AUTOSAR XML (schema 4-3-0)
package /MICROSAR/BswM_swc
  data type mapping set BswMMappingSet  # Contains Mapping for ModeDeclarations Groups which are provided by BswM.
    mode-request-type-maps:
      implementation-data-type=uint8, mode-group=ErrorMemoryLockSignalReceptionMode
      implementation-data-type=uint8, mode-group=StdDiag_SessionModeGroup
      implementation-data-type=NormalCommunicationModeType, mode-group=StdDiag_NormalCommunicationModeGroup
      implementation-data-type=uint8, mode-group=Vin_VinComMode
      implementation-data-type=uint8, mode-group=DarhReportErrorMode
      implementation-data-type=Coding_ConditionModeType, mode-group=Coding_ConditionMode
      implementation-data-type=uint8, mode-group=Coding_BusComMode
      implementation-data-type=Dlog_LifeCycleRequestType, mode-group=Dlog_LifeCycle
      implementation-data-type=StdDiag_LifeCycleRequestType, mode-group=StdDiag_LifeCycle
      implementation-data-type=SysTime_LifeCycleRequestType, mode-group=SysTime_LifeCycle
      implementation-data-type=Omc_LifeCycleRequestType, mode-group=Omc_LifeCycle
      implementation-data-type=Dcm_DiagnosticSessionControlType, mode-group=DcmDiagnosticSessionControl
      implementation-data-type=Darh_LifeCycleRequestType, mode-group=Darh_LifeCycle
      implementation-data-type=Vin_LifeCycleRequestType, mode-group=Vin_LifeCycle
      implementation-data-type=Dcm_EcuResetType, mode-group=DcmEcuReset
      implementation-data-type=Dcm_CommunicationModeType, mode-group=DcmCommunicationControl
      implementation-data-type=Coding_LifeCycleRequestType, mode-group=Coding_LifeCycle
      implementation-data-type=Stm_CentralErrorLockType, mode-group=Stm_CentralErrorLockMode
package /MICROSAR/BswM_swc/ComponentTypes
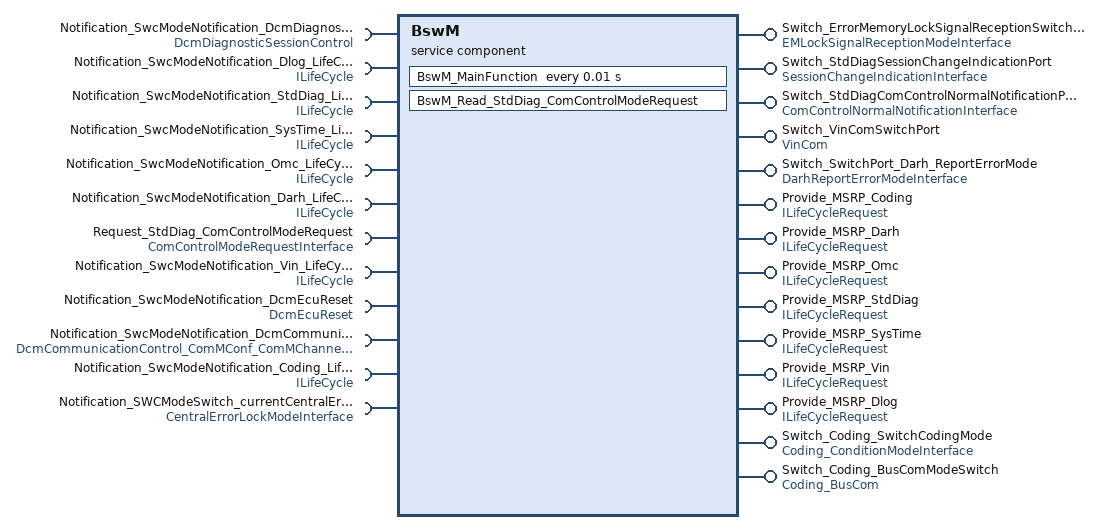
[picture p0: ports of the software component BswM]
  service sw component type BswM: category=SERVICE_COMPONENT
    require port Notification_SwcModeNotification_DcmDiagnosticSessionControl: required-interface=DcmDiagnosticSessionControl
    provide port Switch_ErrorMemoryLockSignalReceptionSwitchPort: provided-interface=EMLockSignalReceptionModeInterface
    provide port Switch_StdDiagSessionChangeIndicationPort: provided-interface=SessionChangeIndicationInterface
    provide port Switch_StdDiagComControlNormalNotificationPort: provided-interface=ComControlNormalNotificationInterface
    6 x require port:
      Notification_SwcModeNotification_Dlog_LifeCycle: required-interface=ILifeCycle
      Notification_SwcModeNotification_StdDiag_LifeCycle: required-interface=ILifeCycle
      Notification_SwcModeNotification_SysTime_LifeCycle: required-interface=ILifeCycle
      Notification_SwcModeNotification_Omc_LifeCycle: required-interface=ILifeCycle
      Notification_SwcModeNotification_Darh_LifeCycle: required-interface=ILifeCycle
      Request_StdDiag_ComControlModeRequest: nonqueued-receiver-com-spec{data-element=requestedMode, handle-out-of-range-status=SILENT, init-value=DISABLE_RX_AND_TX_NORMAL}, required-interface=ComControlModeRequestInterface
    provide port Switch_VinComSwitchPort: provided-interface=VinCom
    4 x require port:
      Notification_SwcModeNotification_Vin_LifeCycle: required-interface=ILifeCycle
      Notification_SwcModeNotification_DcmEcuReset: required-interface=DcmEcuReset
      Notification_SwcModeNotification_DcmCommunicationControl_ComMConf_ComMChannel_A_FlexRay_372befd6: required-interface=DcmCommunicationControl_ComMConf_ComMChannel_A_FlexRay_372befd6
      Notification_SwcModeNotification_Coding_LifeCycle: required-interface=ILifeCycle
    provide port Switch_SwitchPort_Darh_ReportErrorMode: provided-interface=DarhReportErrorModeInterface
    require port Notification_SWCModeSwitch_currentCentralErrorLockMode: required-interface=CentralErrorLockModeInterface
    9 x provide port:
      Provide_MSRP_Coding: nonqueued-sender-com-spec=requestMode, provided-interface=ILifeCycleRequest
      Provide_MSRP_Darh: nonqueued-sender-com-spec=requestMode, provided-interface=ILifeCycleRequest
      Provide_MSRP_Omc: nonqueued-sender-com-spec=requestMode, provided-interface=ILifeCycleRequest
      Provide_MSRP_StdDiag: nonqueued-sender-com-spec{data-element=requestMode, init-value=STDDIAG_STOPPED}, provided-interface=ILifeCycleRequest
      Provide_MSRP_SysTime: nonqueued-sender-com-spec=requestMode, provided-interface=ILifeCycleRequest
      Provide_MSRP_Vin: nonqueued-sender-com-spec{data-element=requestMode, init-value=VIN_STOPPED}, provided-interface=ILifeCycleRequest
      Provide_MSRP_Dlog: nonqueued-sender-com-spec=requestMode, provided-interface=ILifeCycleRequest
      Switch_Coding_SwitchCodingMode: provided-interface=Coding_ConditionModeInterface
      Switch_Coding_BusComModeSwitch: provided-interface=Coding_BusCom
    behavior BswMInternalBehavior: data-type-mapping=BswMMappingSet, handle-termination-and-restart=NO-SUPPORT
      timing event Timer_BswM_MainFunction: start-on-event=BswM_MainFunction, period=0.01
      data received event DataReceivedEvent_BswM_Read_StdDiag_ComControlModeRequest_Request_StdDiag_ComControlModeRequest_requestedMode: start-on-event=BswM_Read_StdDiag_ComControlModeRequest, data=Request_StdDiag_ComControlModeRequest.requestedMode
      port-api-options:
        enable-take-address=true, indirect-api=false, port=Notification_SwcModeNotification_DcmDiagnosticSessionControl
        enable-take-address=true, indirect-api=false, port=Switch_ErrorMemoryLockSignalReceptionSwitchPort
        enable-take-address=true, indirect-api=false, port=Switch_StdDiagSessionChangeIndicationPort
        enable-take-address=true, indirect-api=false, port=Switch_StdDiagComControlNormalNotificationPort
        enable-take-address=true, indirect-api=false, port=Notification_SwcModeNotification_Dlog_LifeCycle
        enable-take-address=true, indirect-api=false, port=Notification_SwcModeNotification_StdDiag_LifeCycle
        enable-take-address=true, indirect-api=false, port=Notification_SwcModeNotification_SysTime_LifeCycle
        enable-take-address=true, indirect-api=false, port=Notification_SwcModeNotification_Omc_LifeCycle
        enable-take-address=true, indirect-api=false, port=Notification_SwcModeNotification_Darh_LifeCycle
        enable-take-address=true, indirect-api=false, port=Request_StdDiag_ComControlModeRequest
        enable-take-address=true, indirect-api=false, port=Switch_VinComSwitchPort
        enable-take-address=true, indirect-api=false, port=Notification_SwcModeNotification_Vin_LifeCycle
        enable-take-address=true, indirect-api=false, port=Notification_SwcModeNotification_DcmEcuReset
        enable-take-address=true, indirect-api=false, port=Notification_SwcModeNotification_DcmCommunicationControl_ComMConf_ComMChannel_A_FlexRay_372befd6
        enable-take-address=true, indirect-api=false, port=Notification_SwcModeNotification_Coding_LifeCycle
        enable-take-address=true, indirect-api=false, port=Switch_SwitchPort_Darh_ReportErrorMode
        enable-take-address=true, indirect-api=false, port=Notification_SWCModeSwitch_currentCentralErrorLockMode
        enable-take-address=true, indirect-api=false, port=Provide_MSRP_Coding
        enable-take-address=true, indirect-api=false, port=Provide_MSRP_Darh
        enable-take-address=true, indirect-api=false, port=Provide_MSRP_Omc
        enable-take-address=true, indirect-api=false, port=Provide_MSRP_StdDiag
        enable-take-address=true, indirect-api=false, port=Provide_MSRP_SysTime
        enable-take-address=true, indirect-api=false, port=Provide_MSRP_Vin
        enable-take-address=true, indirect-api=false, port=Provide_MSRP_Dlog
        enable-take-address=true, indirect-api=false, port=Switch_Coding_SwitchCodingMode
        enable-take-address=true, indirect-api=false, port=Switch_Coding_BusComModeSwitch
      runnable BswM_MainFunction
        data-send-points:
          7 x access:
            DataSendPointBswM_MainFunction_Provide_MSRP_Coding_requestMode: accessed-variable=Provide_MSRP_Coding.requestMode
            DataSendPointBswM_MainFunction_Provide_MSRP_Darh_requestMode: accessed-variable=Provide_MSRP_Darh.requestMode
            DataSendPointBswM_MainFunction_Provide_MSRP_Omc_requestMode: accessed-variable=Provide_MSRP_Omc.requestMode
            DataSendPointBswM_MainFunction_Provide_MSRP_StdDiag_requestMode: accessed-variable=Provide_MSRP_StdDiag.requestMode
            DataSendPointBswM_MainFunction_Provide_MSRP_SysTime_requestMode: accessed-variable=Provide_MSRP_SysTime.requestMode
            DataSendPointBswM_MainFunction_Provide_MSRP_Vin_requestMode: accessed-variable=Provide_MSRP_Vin.requestMode
            DataSendPointBswM_MainFunction_Provide_MSRP_Dlog_requestMode: accessed-variable=Provide_MSRP_Dlog.requestMode
        mode-access-points:
          Notification_SwcModeNotification_DcmDiagnosticSessionControl.DcmDiagnosticSessionControl
          Notification_SwcModeNotification_Dlog_LifeCycle.Mode
          Notification_SwcModeNotification_StdDiag_LifeCycle.Mode
          Notification_SwcModeNotification_SysTime_LifeCycle.Mode
          Notification_SwcModeNotification_Omc_LifeCycle.Mode
          Notification_SwcModeNotification_Darh_LifeCycle.Mode
          Notification_SwcModeNotification_Vin_LifeCycle.Mode
          Notification_SwcModeNotification_DcmCommunicationControl_ComMConf_ComMChannel_A_FlexRay_372befd6.DcmCommunicationControl_ComMConf_ComMChannel_A_FlexRay_372befd6
          Notification_SwcModeNotification_Coding_LifeCycle.Mode
          Notification_SWCModeSwitch_currentCentralErrorLockMode.currentCentralErrorLockMode
          Notification_SwcModeNotification_DcmEcuReset.DcmEcuReset
        7 x mode switch point:
          ModeSwitchPointBswM_MainFunction_Switch_ErrorMemoryLockSignalReceptionSwitchPort_currentEMLockSignalReceptionMode: mode-group=Switch_ErrorMemoryLockSignalReceptionSwitchPort.currentEMLockSignalReceptionMode
          ModeSwitchPointBswM_MainFunction_Switch_StdDiagSessionChangeIndicationPort_SessionModeDeclarationGroup: mode-group=Switch_StdDiagSessionChangeIndicationPort.SessionModeDeclarationGroup
          ModeSwitchPointBswM_MainFunction_Switch_StdDiagComControlNormalNotificationPort_CommunicationModeDeclarationGroup: mode-group=Switch_StdDiagComControlNormalNotificationPort.CommunicationModeDeclarationGroup
          ModeSwitchPointBswM_MainFunction_Switch_VinComSwitchPort_Mode: mode-group=Switch_VinComSwitchPort.Mode
          ModeSwitchPointBswM_MainFunction_Switch_SwitchPort_Darh_ReportErrorMode_DarhReportErrorMode: mode-group=Switch_SwitchPort_Darh_ReportErrorMode.DarhReportErrorMode
          ModeSwitchPointBswM_MainFunction_Switch_Coding_SwitchCodingMode_currentConditionMode: mode-group=Switch_Coding_SwitchCodingMode.currentConditionMode
          ModeSwitchPointBswM_MainFunction_Switch_Coding_BusComModeSwitch_Mode: mode-group=Switch_Coding_BusComModeSwitch.Mode
      runnable BswM_Read_StdDiag_ComControlModeRequest: can-be-invoked-concurrently=true
        data-receive-point-by-arguments:
          access DataReceivePointBswM_Read_StdDiag_ComControlModeRequest_Request_StdDiag_ComControlModeRequest_requestedMode: accessed-variable=Request_StdDiag_ComControlModeRequest.requestedMode
  swc implementation BswMImplementation: programming-language=C, behavior=BswMInternalBehavior
